# AltaRiscv register map
File version: 1.0
Registers are 32-bit, read-write, reset 0x0 unless marked. A register's access mark holds for its fields unless they carry their own. Offsets are from the block's base; [hi:lo] are bit positions; {n}, {i} and the like mark numbered series; 'fields as' and 'values as' point back to an identical list.

## GPTIMER0 — GPTIMER registers
Base 0x40020000
Same registers: GPTIMER1 0x40021000, GPTIMER2 0x40022000, GPTIMER3 0x40023000, GPTIMER4 0x40024000
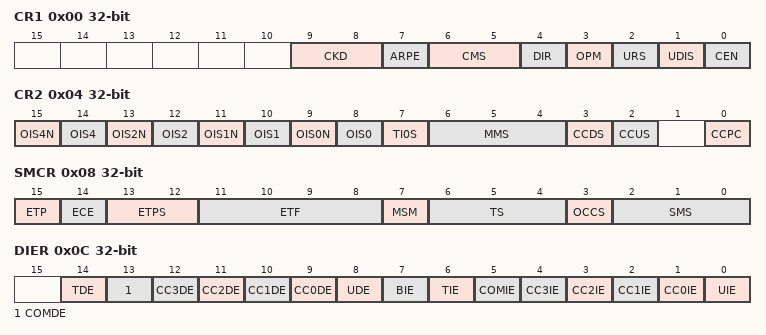
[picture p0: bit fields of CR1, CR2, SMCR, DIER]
0x00 CR1 — Control register 1
  [9:8] CKD — Clock division
    0=Div 1; 1=Div 2; 2=Div 4; 3=Div 8
  [7] ARPE — Auto-reload preload enable
  [6:5] CMS — Center-aligned mode selection
    0=Edge-aligned; 1=Center-aligned 1; 2=Center-aligned 2; 3=Center-aligned 3
  [4] DIR — Direction
    0=Up counter; 1=Down counter
  [3] OPM — One pulse mode
  [2] URS — Update request source
    0=All sources; 1=Counter overflow/underflow
  [1] UDIS — Update disable
    0=UEV enabled; 1=UEV disabled
  [0] CEN — Counter enable
0x04 CR2 — Control register 2
  [15] OIS4N — OC3N idle state
  [14] OIS4 — OC3 idle state
  [13] OIS2N — OC2N idle state
  [12] OIS2 — OC2 idle state
  [11] OIS1N — OC1N idle state
  [10] OIS1 — OC1 idle state
  [9] OIS0N — OC0N idle state
  [8] OIS0 — OC0 idle state
  [7] TI0S — TI0 selection
    0=TI0; 1=XOR of TI0/TI1/TI2
  [6:4] MMS — Master mode selection
    0=Reset; 1=Enable; 2=Update; 3=Compare Pulse; {v}=OC{v-4}REF (v=4..7)
  [3] CCDS — Capture/Compare DMA selection
    0=CCx; 1=Update
  [2] CCUS — Capture/Compare control update selection
    0=COMG; 1=COMG and TRGI
  [0] CCPC — Capture/Compare preloaded control
0x08 SMCR — Slave mode control register
  [15] ETP — External trigger polarity
    0=Non-inverted; 1=Inverted
  [14] ECE — External clock enable
  [13:12] ETPS — External trigger prescaler
    0=Div 1; 1=Div 2; 2=Div 4; 3=Div 8
  [11:8] ETF — External trigger filter
    0=FDIV1; 1=FDIV1_N2; 2=FDIV1_N4; 3=FDIV1_N8; 4=FDIV2_N6; 5=FDIV2_N8; 6=FDIV4_N6; 7=FDIV4_N8; 8=FDIV8_N6; 9=FDIV8_N8; 10=FDIV16_N5; 11=FDIV16_N6; 12=FDIV16_N8; 13=FDIV32_N5; 14=FDIV32_N6; 15=FDIV32_N8
  [7] MSM — Master/slave mode
  [6:4] TS — Trigger selection
    {v}=ITR{v} (v=0..3); 4=TI1F_ED; 5=TI0FP0; 6=TI1FP1; 7=ETRF
  [3] OCCS — OCREF clear selection
    0=OCREF_CLR; 1=ETRF
  [2:0] SMS — Slave mode selection
    0=Disabled; 1=Encoder 1; 2=Encoder 2; 3=Encoder 3; 4=Reset; 5=Gated; 6=Trigger; 7=External Clock 1
0x0C DIER — DMA/interrupt enable register
  [14] TDE — Trigger DMA request enable
  [13] COMDE — COM DMA request enable
  [n+9] CC{n}DE (n=0..3) — Capture/Compare {n} DMA request enable
  [8] UDE — Update DMA request enable
  [7] BIE — Break interrupt enable
  [6] TIE — Trigger interrupt enable
  [5] COMIE — COM interrupt enable
  [n+1] CC{n}IE (n=0..3) — Capture/Compare {n} interrupt enable
  [0] UIE — Update interrupt enable
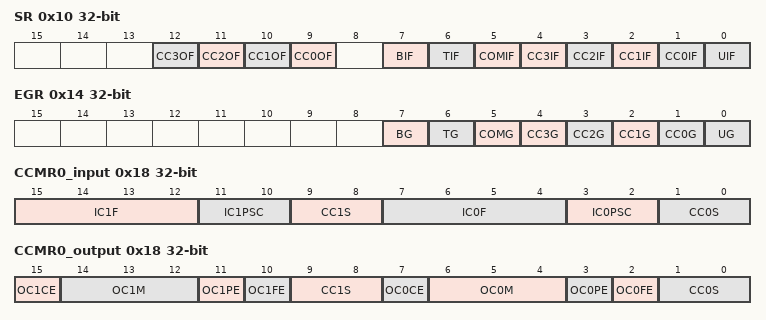
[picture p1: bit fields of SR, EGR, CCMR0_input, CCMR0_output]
0x10 SR — Status register
  [n+9] CC{n}OF (n=0..3) — Capture/Compare {n} overcapture flag
  [7] BIF — Break interrupt flag
  [6] TIF — Trigger interrupt flag
  [5] COMIF — COM interrupt flag
  [n+1] CC{n}IF (n=0..3) — Capture/Compare {n} interrupt flag
  [0] UIF — Update interrupt flag
0x14 EGR wo — Event generation register
  [7] BG — Break generation
  [6] TG — Trigger generation
  [5] COMG — Capture/Compare control update generation
  [n+1] CC{n}G (n=0..3) — Capture/Compare {n} generation
  [0] UG — Update generation
0x18 CCMR0_input — Capture/compare mode register 0
  [15:12] IC1F — Input capture 1 filter
    values as SMCR.ETF
  [11:10] IC1PSC — Input capture 1 prescaler
    0=Div 1; 1=Div 2; 2=Div 4; 3=Div 8
  [9:8] CC1S — Capture/Compare 1 selection
    0=Output; 1=Input direct; 2=Input indirect; 3=Input TRC
  [7:4] IC0F — Input capture 0 filter
    values as SMCR.ETF
  [3:2] IC0PSC — Input capture 0 prescaler
    0=Div 1; 1=Div 2; 2=Div 4; 3=Div 8
  [1:0] CC0S — Capture/Compare 0 selection
    0=Output; 1=Input direct; 2=Input indirect; 3=Input TRC
0x18 CCMR0_output (alternate view of CCMR0_input) — Capture/compare mode register 0
  [15] OC1CE — Output compare 1 clear enable
  [14:12] OC1M — Output compare 1 mode
    0=Frozen; 1=Active; 2=Inactive; 3=Toggle; 4=Forced inactive; 5=Forced active; 6=Pwm1; 7=Pwm2
  [11] OC1PE — Output compare 1 preload enable
  [10] OC1FE — Output compare 1 fast enable
  [9:8] CC1S — Capture/Compare 1 selection
    0=Output; 1=Input direct; 2=Input indirect; 3=Input TRC
  [7] OC0CE — Output compare 0 clear enable
  [6:4] OC0M — Output compare 0 mode
    values as OC1M
  [3] OC0PE — Output compare 0 preload enable
  [2] OC0FE — Output compare 0 fast enable
  [1:0] CC0S — Capture/Compare 0 selection
    0=Output; 1=Input direct; 2=Input indirect; 3=Input TRC
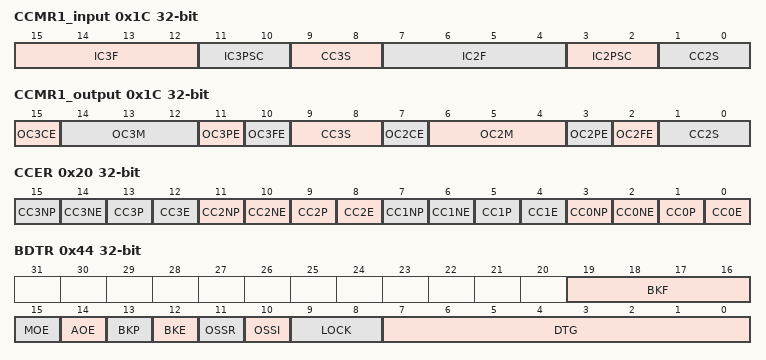
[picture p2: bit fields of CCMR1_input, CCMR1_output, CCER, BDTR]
0x1C CCMR1_input — Capture/compare mode register 1
  [15:12] IC3F — Input capture 3 filter
    values as SMCR.ETF
  [11:10] IC3PSC — Input capture 3 prescaler
    0=Div 1; 1=Div 2; 2=Div 4; 3=Div 8
  [9:8] CC3S — Capture/Compare 3 selection
    0=Output; 1=Input direct; 2=Input indirect; 3=Input TRC
  [7:4] IC2F — Input capture 2 filter
    values as SMCR.ETF
  [3:2] IC2PSC — Input capture 2 prescaler
    0=Div 1; 1=Div 2; 2=Div 4; 3=Div 8
  [1:0] CC2S — Capture/Compare 2 selection
    0=Output; 1=Input direct; 2=Input indirect; 3=Input TRC
0x1C CCMR1_output (alternate view of CCMR1_input) — Capture/compare mode register 1
  [15] OC3CE — Output compare 3 clear enable
  [14:12] OC3M — Output compare 3 mode
    values as CCMR0_output.OC1M
  [11] OC3PE — Output compare 3 preload enable
  [10] OC3FE — Output compare 3 fast enable
  [9:8] CC3S — Capture/Compare 3 selection
    0=Output; 1=Input direct; 2=Input indirect; 3=Input TRC
  [7] OC2CE — Output compare 2 clear enable
  [6:4] OC2M — Output compare 2 mode
    values as CCMR0_output.OC1M
  [3] OC2PE — Output compare 2 preload enable
  [2] OC2FE — Output compare 2 fast enable
  [1:0] CC2S — Capture/Compare 2 selection
    0=Output; 1=Input direct; 2=Input indirect; 3=Input TRC
0x20 CCER — Capture/compare enable register
  [4n+3] CC{n}NP (n=0..3) — Capture/Compare {n} complementary output polarity
    0=Active High; 1=Active Low
  [4n+2] CC{n}NE (n=0..3) — Capture/Compare {n} complementary output enable
  [4n+1] CC{n}P (n=0..3) — Capture/Compare {n} output polarity
    0=Active High; 1=Active Low
  [4n] CC{n}E (n=0..3) — Capture/Compare {n} output enable
0x24 CNT — Counter
0x28 PSC — Prescaler
  [15:0] PSC
0x2C ARR — Auto reload register
0x30 RCR — Repetition counter register
  [15:0] RCR
{0x34+4i} CCR{i} (i=0..3) — Capture compare register {i}
0x44 BDTR — Break and dead time register
  [19:16] BKF — Break filter
    values as SMCR.ETF
  [15] MOE — Main output enable
  [14] AOE — Automatic output enable
  [13] BKP — Break polarity
    0=Active Low; 1=Active High
  [12] BKE — Break enable
  [11] OSSR — Off-State selection for run mode
  [10] OSSI — Off-State selection for idle mode
  [9:8] LOCK — Lock configuration
    0=Lock Off; 1=Lock Level 1; 2=Lock Level 2; 3=Lock Level 3
  [7:0] DTG — Dead-Time generator setup
